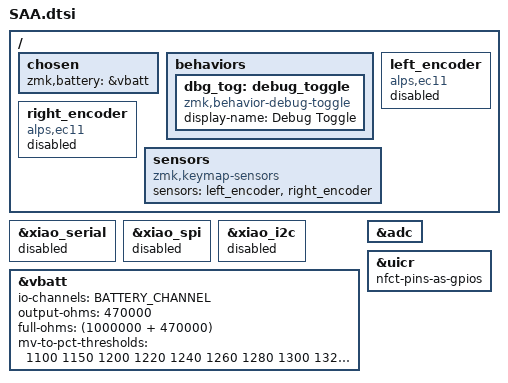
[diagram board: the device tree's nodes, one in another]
#include "SAA_pins.dtsi"
#include "SAA_layout.dtsi"
#include "SAA_led.dtsi"
#include "SAA_oled.dtsi"

/ {
	chosen {
		zmk,battery = &vbatt;
	};

	behaviors {
		dbg_tog: debug_toggle {
			compatible = "zmk,behavior-debug-toggle";
			#binding-cells = <0>;
			display-name = "Debug Toggle";
		};
	};

	// Encoders
	left_encoder: left_encoder {
		compatible = "alps,ec11";
		status = "disabled";
	};

	right_encoder: right_encoder {
		compatible = "alps,ec11";
		status = "disabled";
	};

	sensors: sensors {
		compatible = "zmk,keymap-sensors";
		sensors = <&left_encoder &right_encoder>;
	};

};

// Release the board-default buses; module overlays enable their own pinctrl.
&xiao_serial {
	status = "disabled";
};

&xiao_spi {
	status = "disabled";
};

&xiao_i2c {
	status = "disabled";
};

// Override the ZMK board variant's battery node with SAA's existing divider.
&vbatt {
	io-channels = BATTERY_CHANNEL;
	/delete-property/ power-gpios;
	output-ohms = <470000>;
	full-ohms = <(1000000 + 470000)>;
	// For Ni-Mh 1U
	mv-to-pct-thresholds = <1100 1150 1200 1220 1240 1260 1280 1300 1320 1350 1400>;
};

&adc {
	status = "okay";
};

&uicr {
	nfct-pins-as-gpios;
};
